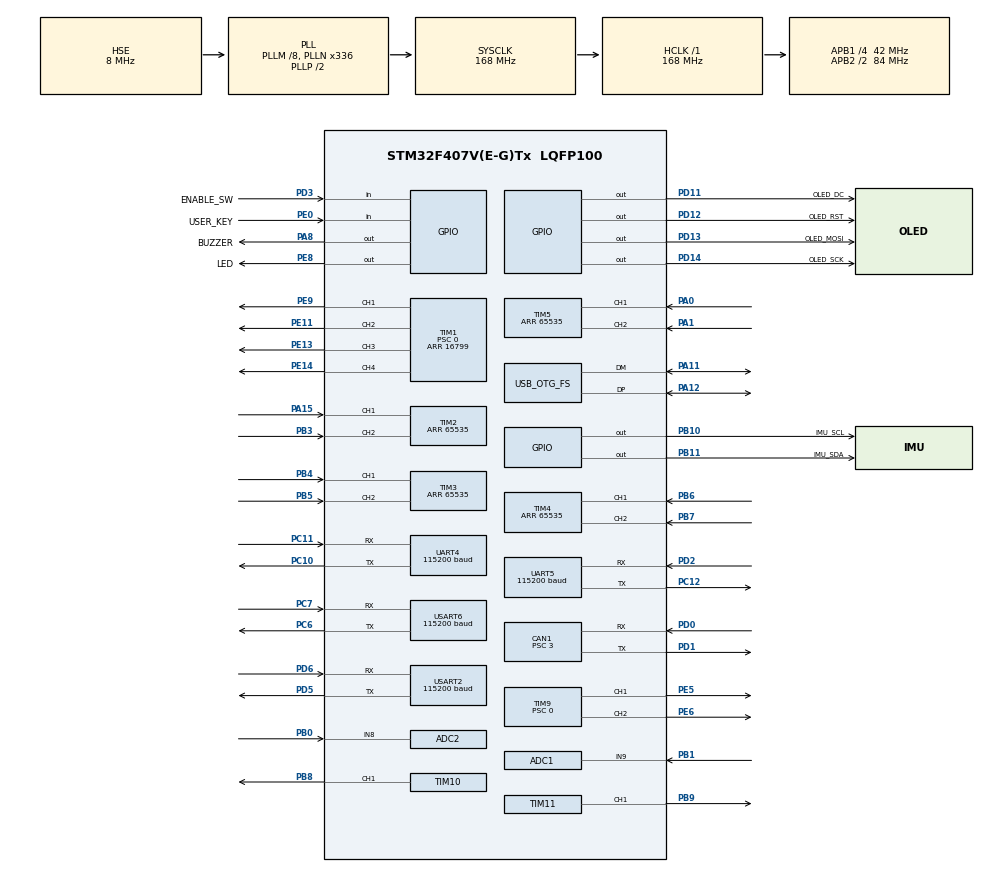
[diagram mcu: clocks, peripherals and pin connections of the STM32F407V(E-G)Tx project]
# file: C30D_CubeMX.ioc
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ADC1.Channel-0\#ChannelRegularConversion=ADC_CHANNEL_9
ADC1.ClockPrescaler=ADC_CLOCK_SYNC_PCLK_DIV6
ADC1.NbrOfConversionFlag=1
ADC1.Rank-0\#ChannelRegularConversion=1
ADC1.SamplingTime-0\#ChannelRegularConversion=ADC_SAMPLETIME_480CYCLES
ADC1.master=1
ADC2.Channel-0\#ChannelRegularConversion=ADC_CHANNEL_8
ADC2.ClockPrescaler=ADC_CLOCK_SYNC_PCLK_DIV6
ADC2.NbrOfConversionFlag=1
ADC2.Rank-0\#ChannelRegularConversion=1
ADC2.SamplingTime-0\#ChannelRegularConversion=ADC_SAMPLETIME_480CYCLES
CAN1.BS1=CAN_BS1_6TQ
CAN1.BS2=CAN_BS2_7TQ
CAN1.CalculateBaudRate=1000000
CAN1.CalculateTimeQuantum=71.42857142857143
CAN1.NART=DISABLE
CAN1.Prescaler=3
Dma.Request0=USART6_RX
Dma.Request1=UART4_RX
Dma.Request2=UART5_RX
Dma.UART4_RX.1.Direction=DMA_PERIPH_TO_MEMORY
Dma.UART4_RX.1.FIFOMode=DMA_FIFOMODE_DISABLE
Dma.UART4_RX.1.Instance=DMA1_Stream2
Dma.UART4_RX.1.MemDataAlignment=DMA_MDATAALIGN_BYTE
Dma.UART4_RX.1.MemInc=DMA_MINC_ENABLE
Dma.UART4_RX.1.Mode=DMA_CIRCULAR
Dma.UART4_RX.1.PeriphDataAlignment=DMA_PDATAALIGN_BYTE
Dma.UART4_RX.1.PeriphInc=DMA_PINC_DISABLE
Dma.UART4_RX.1.Priority=DMA_PRIORITY_HIGH
Dma.UART5_RX.2.Direction=DMA_PERIPH_TO_MEMORY
Dma.UART5_RX.2.FIFOMode=DMA_FIFOMODE_DISABLE
Dma.UART5_RX.2.Instance=DMA1_Stream0
Dma.UART5_RX.2.MemDataAlignment=DMA_MDATAALIGN_BYTE
Dma.UART5_RX.2.MemInc=DMA_MINC_ENABLE
Dma.UART5_RX.2.Mode=DMA_CIRCULAR
Dma.UART5_RX.2.PeriphDataAlignment=DMA_PDATAALIGN_BYTE
Dma.UART5_RX.2.PeriphInc=DMA_PINC_DISABLE
Dma.UART5_RX.2.Priority=DMA_PRIORITY_HIGH
Dma.USART6_RX.0.Direction=DMA_PERIPH_TO_MEMORY
Dma.USART6_RX.0.FIFOMode=DMA_FIFOMODE_DISABLE
Dma.USART6_RX.0.Instance=DMA2_Stream1
Dma.USART6_RX.0.MemDataAlignment=DMA_MDATAALIGN_BYTE
Dma.USART6_RX.0.MemInc=DMA_MINC_ENABLE
Dma.USART6_RX.0.Mode=DMA_CIRCULAR
Dma.USART6_RX.0.PeriphDataAlignment=DMA_PDATAALIGN_BYTE
Dma.USART6_RX.0.PeriphInc=DMA_PINC_DISABLE
Dma.USART6_RX.0.Priority=DMA_PRIORITY_HIGH
FREERTOS.Tasks01=defaultTask,24,128,StartDefaultTask,Default,NULL,Dynamic,NULL,NULL
IWDG.Prescaler=IWDG_PRESCALER_64
IWDG.Reload=500
Mcu.Family=STM32F4
Mcu.Name=STM32F407V(E-G)Tx
Mcu.Package=LQFP100
NVIC.CAN1_RX0_IRQn=true\:5\:0\:false\:false\:true\:true\:true\:true\:true
NVIC.DMA1_Stream0_IRQn=true\:5\:0\:false\:false\:true\:true\:false\:true\:true
NVIC.DMA1_Stream2_IRQn=true\:5\:0\:false\:false\:true\:true\:false\:true\:true
NVIC.DMA2_Stream1_IRQn=true\:5\:0\:false\:false\:true\:true\:false\:true\:true
NVIC.OTG_FS_IRQn=true\:5\:0\:false\:false\:true\:true\:true\:true\:true
NVIC.PriorityGroup=NVIC_PRIORITYGROUP_4
NVIC.TIM6_DAC_IRQn=true\:15\:0\:false\:false\:true\:false\:true\:true\:true
NVIC.TimeBase=TIM6_DAC_IRQn
NVIC.TimeBaseIP=TIM6
PA0-WKUP.GPIO_ModeDefaultInputPP=GPIO_MODE_AF_OD
PA0-WKUP.GPIO_PuPd=GPIO_PULLUP
PA0-WKUP.GPIO_Speed=GPIO_SPEED_FREQ_VERY_HIGH
PA0-WKUP.Signal=S_TIM5_CH1
PA1.GPIO_ModeDefaultInputPP=GPIO_MODE_AF_OD
PA1.GPIO_PuPd=GPIO_PULLUP
PA1.GPIO_Speed=GPIO_SPEED_FREQ_VERY_HIGH
PA1.Signal=S_TIM5_CH2
PA11.Mode=Host_Only
PA11.Signal=USB_OTG_FS_DM
PA12.Mode=Host_Only
PA12.Signal=USB_OTG_FS_DP
PA13.Mode=Serial_Wire
PA13.Signal=SYS_JTMS-SWDIO
PA14.Mode=Serial_Wire
PA14.Signal=SYS_JTCK-SWCLK
PA15.GPIO_ModeDefaultInputPP=GPIO_MODE_AF_OD
PA15.GPIO_PuPd=GPIO_PULLUP
PA15.GPIO_Speed=GPIO_SPEED_FREQ_VERY_HIGH
PA15.Signal=S_TIM2_CH1_ETR
PA8.GPIO_Label=BUZZER
PA8.Signal=GPIO_Output
PB0.Signal=ADCx_IN8
PB1.Signal=ADCx_IN9
PB10.GPIO_Label=IMU_SCL
PB10.GPIO_PuPd=GPIO_PULLUP
PB10.PinState=GPIO_PIN_SET
PB10.Signal=GPIO_Output
PB11.GPIO_Label=IMU_SDA
PB11.GPIO_PuPd=GPIO_PULLUP
PB11.PinState=GPIO_PIN_SET
PB11.Signal=GPIO_Output
PB3.GPIO_ModeDefaultInputPP=GPIO_MODE_AF_OD
PB3.GPIO_PuPd=GPIO_PULLUP
PB3.GPIO_Speed=GPIO_SPEED_FREQ_VERY_HIGH
PB3.Signal=S_TIM2_CH2
PB4.GPIO_ModeDefaultInputPP=GPIO_MODE_AF_OD
PB4.GPIO_PuPd=GPIO_PULLUP
PB4.GPIO_Speed=GPIO_SPEED_FREQ_VERY_HIGH
PB4.Signal=S_TIM3_CH1
PB5.GPIO_ModeDefaultInputPP=GPIO_MODE_AF_OD
PB5.GPIO_PuPd=GPIO_PULLUP
PB5.GPIO_Speed=GPIO_SPEED_FREQ_VERY_HIGH
PB5.Signal=S_TIM3_CH2
PB6.GPIO_ModeDefaultInputPP=GPIO_MODE_AF_OD
PB6.GPIO_PuPd=GPIO_PULLUP
PB6.GPIO_Speed=GPIO_SPEED_FREQ_VERY_HIGH
PB6.Signal=S_TIM4_CH1
PB7.GPIO_ModeDefaultInputPP=GPIO_MODE_AF_OD
PB7.GPIO_PuPd=GPIO_PULLUP
PB7.GPIO_Speed=GPIO_SPEED_FREQ_VERY_HIGH
PB7.Signal=S_TIM4_CH2
PB8.GPIO_PuPd=GPIO_PULLUP
PB8.GPIO_Speed=GPIO_SPEED_FREQ_VERY_HIGH
PB8.Signal=S_TIM10_CH1
PB9.GPIO_PuPd=GPIO_PULLUP
PB9.GPIO_Speed=GPIO_SPEED_FREQ_VERY_HIGH
PB9.Signal=S_TIM11_CH1
PC10.GPIO_PuPd=GPIO_PULLUP
PC10.GPIO_Speed=GPIO_SPEED_FREQ_HIGH
PC10.Mode=Asynchronous
PC10.Signal=UART4_TX
PC11.GPIO_PuPd=GPIO_PULLUP
PC11.GPIO_Speed=GPIO_SPEED_FREQ_HIGH
PC11.Mode=Asynchronous
PC11.Signal=UART4_RX
PC12.GPIO_PuPd=GPIO_PULLUP
PC12.GPIO_Speed=GPIO_SPEED_FREQ_HIGH
PC12.Mode=Asynchronous
PC12.Signal=UART5_TX
PC6.GPIO_PuPd=GPIO_PULLUP
PC6.GPIO_Speed=GPIO_SPEED_FREQ_HIGH
PC6.Mode=Asynchronous
PC6.Signal=USART6_TX
PC7.GPIO_PuPd=GPIO_PULLUP
PC7.GPIO_Speed=GPIO_SPEED_FREQ_HIGH
PC7.Mode=Asynchronous
PC7.Signal=USART6_RX
PD0.Mode=CAN_Activate
PD0.Signal=CAN1_RX
PD1.Mode=CAN_Activate
PD1.Signal=CAN1_TX
PD11.GPIO_Label=OLED_DC
PD11.Signal=GPIO_Output
PD12.GPIO_Label=OLED_RST
PD12.Signal=GPIO_Output
PD13.GPIO_Label=OLED_MOSI
PD13.Signal=GPIO_Output
PD14.GPIO_Label=OLED_SCK
PD14.Signal=GPIO_Output
PD2.GPIO_PuPd=GPIO_PULLUP
PD2.GPIO_Speed=GPIO_SPEED_FREQ_HIGH
PD2.Mode=Asynchronous
PD2.Signal=UART5_RX
PD3.GPIO_Label=ENABLE_SW
PD3.GPIO_PuPd=GPIO_PULLDOWN
PD3.Signal=GPIO_Input
PD5.GPIO_PuPd=GPIO_PULLUP
PD5.GPIO_Speed=GPIO_SPEED_FREQ_HIGH
PD5.Mode=Asynchronous
PD5.Signal=USART2_TX
PD6.GPIO_PuPd=GPIO_PULLUP
PD6.GPIO_Speed=GPIO_SPEED_FREQ_HIGH
PD6.Mode=Asynchronous
PD6.Signal=USART2_RX
PE0.GPIO_Label=USER_KEY
PE0.GPIO_PuPd=GPIO_PULLUP
PE0.Signal=GPIO_Input
PE11.GPIO_PuPd=GPIO_PULLUP
PE11.GPIO_Speed=GPIO_SPEED_FREQ_VERY_HIGH
PE11.Signal=S_TIM1_CH2
PE13.GPIO_PuPd=GPIO_PULLUP
PE13.GPIO_Speed=GPIO_SPEED_FREQ_VERY_HIGH
PE13.Signal=S_TIM1_CH3
PE14.GPIO_PuPd=GPIO_PULLUP
PE14.GPIO_Speed=GPIO_SPEED_FREQ_VERY_HIGH
PE14.Signal=S_TIM1_CH4
PE5.GPIO_PuPd=GPIO_PULLUP
PE5.GPIO_Speed=GPIO_SPEED_FREQ_VERY_HIGH
PE5.Signal=S_TIM9_CH1
PE6.GPIO_PuPd=GPIO_PULLUP
PE6.GPIO_Speed=GPIO_SPEED_FREQ_VERY_HIGH
PE6.Signal=S_TIM9_CH2
PE8.GPIO_Label=LED
PE8.PinState=GPIO_PIN_SET
PE8.Signal=GPIO_Output
PE9.GPIO_PuPd=GPIO_PULLUP
PE9.GPIO_Speed=GPIO_SPEED_FREQ_VERY_HIGH
PE9.Signal=S_TIM1_CH1
PH0-OSC_IN.Mode=HSE-External-Oscillator
PH0-OSC_IN.Signal=RCC_OSC_IN
PH1-OSC_OUT.Mode=HSE-External-Oscillator
PH1-OSC_OUT.Signal=RCC_OSC_OUT
ProjectManager.HeapSize=0x200
ProjectManager.StackSize=0x800
ProjectManager.TargetToolchain=CMake
RCC.AHBFreq_Value=168000000
RCC.APB1CLKDivider=RCC_HCLK_DIV4
RCC.APB1Freq_Value=42000000
RCC.APB1TimFreq_Value=84000000
RCC.APB2CLKDivider=RCC_HCLK_DIV2
RCC.APB2Freq_Value=84000000
RCC.APB2TimFreq_Value=168000000
RCC.CortexFreq_Value=168000000
RCC.HCLKFreq_Value=168000000
RCC.HSE_VALUE=8000000
RCC.HSI_VALUE=16000000
RCC.LSE_VALUE=32768
RCC.PLLM=8
RCC.PLLN=336
RCC.PLLQ=7
RCC.SYSCLKFreq_VALUE=168000000
RCC.SYSCLKSource=RCC_SYSCLKSOURCE_PLLCLK
RCC.VCOOutputFreq_Value=336000000
SH.ADCx_IN8.0=ADC2_IN8,IN8
SH.ADCx_IN9.0=ADC1_IN9,IN9
SH.S_TIM10_CH1.0=TIM10_CH1,PWM Generation1 CH1
SH.S_TIM11_CH1.0=TIM11_CH1,PWM Generation1 CH1
SH.S_TIM1_CH1.0=TIM1_CH1,PWM Generation1 CH1
SH.S_TIM1_CH2.0=TIM1_CH2,PWM Generation2 CH2
SH.S_TIM1_CH3.0=TIM1_CH3,PWM Generation3 CH3
SH.S_TIM1_CH4.0=TIM1_CH4,PWM Generation4 CH4
SH.S_TIM2_CH1_ETR.0=TIM2_CH1,Encoder_Interface
SH.S_TIM2_CH2.0=TIM2_CH2,Encoder_Interface
SH.S_TIM3_CH1.0=TIM3_CH1,Encoder_Interface
SH.S_TIM3_CH2.0=TIM3_CH2,Encoder_Interface
SH.S_TIM4_CH1.0=TIM4_CH1,Encoder_Interface
SH.S_TIM4_CH2.0=TIM4_CH2,Encoder_Interface
SH.S_TIM5_CH1.0=TIM5_CH1,Encoder_Interface
SH.S_TIM5_CH2.0=TIM5_CH2,Encoder_Interface
SH.S_TIM9_CH1.0=TIM9_CH1,PWM Generation1 CH1
SH.S_TIM9_CH2.0=TIM9_CH2,PWM Generation2 CH2
TIM1.Channel-PWM\ Generation1\ CH1=TIM_CHANNEL_1
TIM1.Channel-PWM\ Generation2\ CH2=TIM_CHANNEL_2
TIM1.Channel-PWM\ Generation3\ CH3=TIM_CHANNEL_3
TIM1.Channel-PWM\ Generation4\ CH4=TIM_CHANNEL_4
TIM1.Period=16799
TIM1.Prescaler=0
TIM10.Channel=TIM_CHANNEL_1
TIM10.Channel-PWM\ Generation1\ CH1=TIM_CHANNEL_1
TIM10.Period=16799
TIM10.Prescaler=0
TIM11.Channel=TIM_CHANNEL_1
TIM11.Channel-PWM\ Generation1\ CH1=TIM_CHANNEL_1
TIM11.Period=16799
TIM11.Prescaler=0
TIM2.EncoderMode=TIM_ENCODERMODE_TI12
TIM2.Period=65535
TIM3.EncoderMode=TIM_ENCODERMODE_TI12
TIM3.Period=65535
TIM4.EncoderMode=TIM_ENCODERMODE_TI12
TIM4.Period=65535
TIM5.EncoderMode=TIM_ENCODERMODE_TI12
TIM5.Period=65535
TIM9.Channel-PWM\ Generation1\ CH1=TIM_CHANNEL_1
TIM9.Channel-PWM\ Generation2\ CH2=TIM_CHANNEL_2
TIM9.Period=16799
TIM9.Prescaler=0
UART4.BaudRate=115200
UART4.VirtualMode=Asynchronous
UART5.BaudRate=115200
UART5.VirtualMode=Asynchronous
USART2.BaudRate=115200
USART2.VirtualMode=VM_ASYNC
USART6.BaudRate=115200
USART6.VirtualMode=VM_ASYNC
USB_OTG_FS.VirtualMode=Host_Only
USB_OTG_FS.phy_itface=HCD_PHY_EMBEDDED
VP_FREERTOS_VS_CMSIS_V2.Mode=CMSIS_V2
VP_IWDG_VS_IWDG.Mode=IWDG_Activate
VP_SYS_VS_tim6.Mode=TIM6
VP_TIM10_VS_ClockSourceINT.Mode=Enable_Timer
VP_TIM11_VS_ClockSourceINT.Mode=Enable_Timer
board=custom

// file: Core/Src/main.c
/* USER CODE BEGIN Header */
/**
  ******************************************************************************
  * @file           : main.c
  * @brief          : Main program body
  ******************************************************************************
  * @attention
  *
  * Copyright (c) 2026 STMicroelectronics.
  * All rights reserved.
  *
  * This software is licensed under terms that can be found in the LICENSE file
  * in the root directory of this software component.
  * If no LICENSE file comes with this software, it is provided AS-IS.
  *
  ******************************************************************************
  */
/* USER CODE END Header */
#include "main.h"
#include "cmsis_os.h"
#include "adc.h"
#include "can.h"
#include "dma.h"
#include "iwdg.h"
#include "tim.h"
#include "usart.h"
#include "usb_otg.h"
#include "gpio.h"

void SystemClock_Config(void);
void MX_FREERTOS_Init(void);

int main(void)
{

  /* MCU Configuration--------------------------------------------------------*/

  /* Reset of all peripherals, Initializes the Flash interface and the Systick. */
  HAL_Init();

  /* Configure the system clock */
  SystemClock_Config();

  /* Initialize all configured peripherals */
  MX_GPIO_Init();
  MX_DMA_Init();
  MX_ADC1_Init();
  MX_ADC2_Init();
  MX_CAN1_Init();
  MX_TIM1_Init();
  MX_TIM2_Init();
  MX_TIM3_Init();
  MX_TIM4_Init();
  MX_TIM5_Init();
  MX_TIM9_Init();
  MX_TIM10_Init();
  MX_TIM11_Init();
  MX_UART4_Init();
  MX_UART5_Init();
  MX_USART2_UART_Init();
  MX_USART6_UART_Init();
  MX_USB_OTG_FS_HCD_Init();
  MX_IWDG_Init();

  /* Init scheduler */
  osKernelInitialize();  /* Call init function for freertos objects (in cmsis_os2.c) */
  MX_FREERTOS_Init();

  /* Start scheduler */
  osKernelStart();

  /* We should never get here as control is now taken by the scheduler */

  /* Infinite loop */
  while (1)
  {

    /* USER CODE BEGIN 3 */
    HAL_IWDG_Refresh(&hiwdg);
  }
  /* USER CODE END 3 */
}

void SystemClock_Config(void)
{
  RCC_OscInitTypeDef RCC_OscInitStruct = {0};
  RCC_ClkInitTypeDef RCC_ClkInitStruct = {0};

  /** Configure the main internal regulator output voltage
  */
  __HAL_RCC_PWR_CLK_ENABLE();
  __HAL_PWR_VOLTAGESCALING_CONFIG(PWR_REGULATOR_VOLTAGE_SCALE1);

  /** Initializes the RCC Oscillators according to the specified parameters
  * in the RCC_OscInitTypeDef structure.
  */
  RCC_OscInitStruct.OscillatorType = RCC_OSCILLATORTYPE_LSI|RCC_OSCILLATORTYPE_HSE;
  RCC_OscInitStruct.HSEState = RCC_HSE_ON;
  RCC_OscInitStruct.LSIState = RCC_LSI_ON;
  RCC_OscInitStruct.PLL.PLLState = RCC_PLL_ON;
  RCC_OscInitStruct.PLL.PLLSource = RCC_PLLSOURCE_HSE;
  RCC_OscInitStruct.PLL.PLLM = 8;
  RCC_OscInitStruct.PLL.PLLN = 336;
  RCC_OscInitStruct.PLL.PLLP = RCC_PLLP_DIV2;
  RCC_OscInitStruct.PLL.PLLQ = 7;
  if (HAL_RCC_OscConfig(&RCC_OscInitStruct) != HAL_OK)
  {
    Error_Handler();
  }

  /** Initializes the CPU, AHB and APB buses clocks
  */
  RCC_ClkInitStruct.ClockType = RCC_CLOCKTYPE_HCLK|RCC_CLOCKTYPE_SYSCLK
                              |RCC_CLOCKTYPE_PCLK1|RCC_CLOCKTYPE_PCLK2;
  RCC_ClkInitStruct.SYSCLKSource = RCC_SYSCLKSOURCE_PLLCLK;
  RCC_ClkInitStruct.AHBCLKDivider = RCC_SYSCLK_DIV1;
  RCC_ClkInitStruct.APB1CLKDivider = RCC_HCLK_DIV4;
  RCC_ClkInitStruct.APB2CLKDivider = RCC_HCLK_DIV2;

  if (HAL_RCC_ClockConfig(&RCC_ClkInitStruct, FLASH_LATENCY_5) != HAL_OK)
  {
    Error_Handler();
  }
}

void HAL_TIM_PeriodElapsedCallback(TIM_HandleTypeDef *htim)
{
  if (htim->Instance == TIM6)
  {
    HAL_IncTick();
  }
}

void Error_Handler(void)
{
  __disable_irq();
  while (1)
  {
  }
}

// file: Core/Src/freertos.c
/* USER CODE BEGIN Header */
/**
  ******************************************************************************
  * File Name          : freertos.c
  * Description        : FreeRTOS task creation (native API, no CMSIS wrapper).
  ******************************************************************************
  * @attention
  *
  * Copyright (c) 2026 STMicroelectronics.
  * All rights reserved.
  *
  * This software is licensed under terms that can be found in the LICENSE file
  * in the root directory of this software component.
  * If no LICENSE file comes with this software, it is provided AS-IS.
  *
  ******************************************************************************
  */
/* USER CODE END Header */

#include "FreeRTOS.h"
#include "task.h"
#include "main.h"
#include "cmsis_os.h"

/* USER CODE BEGIN Includes */
#include "board.h"
#include "app_tasks.h"
/* USER CODE END Includes */

/* Definitions for defaultTask */
osThreadId_t defaultTaskHandle;
const osThreadAttr_t defaultTask_attributes = {
  .name = "defaultTask",
  .stack_size = 128 * 4,
  .priority = (osPriority_t) osPriorityNormal,
};

void StartDefaultTask(void *argument);

void MX_FREERTOS_Init(void); /* (MISRA C 2004 rule 8.1) */

void MX_FREERTOS_Init(void) {
  /* USER CODE BEGIN Init */
  Board_Init();
  /* USER CODE END Init */

  /* Create the thread(s) */
  /* creation of defaultTask */
  defaultTaskHandle = osThreadNew(StartDefaultTask, NULL, &defaultTask_attributes);

  /* USER CODE BEGIN RTOS_THREADS */
  /* Starts PWM, encoders, UART DMA, ADC and the IMU, then creates the six
     application tasks with xTaskCreateStatic(). */
  App_InitRtos();
  /* USER CODE END RTOS_THREADS */

}

void StartDefaultTask(void *argument)
{
  for(;;)
  {
    osDelay(1);
  }
}
